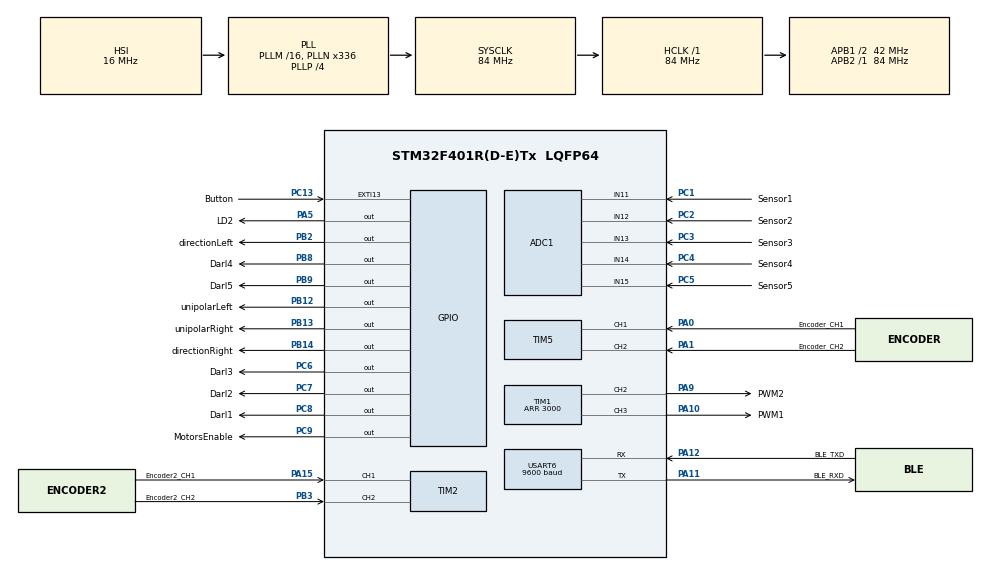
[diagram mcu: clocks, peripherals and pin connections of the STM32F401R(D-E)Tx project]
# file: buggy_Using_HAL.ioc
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ADC1.Channel-0\#ChannelRegularConversion=ADC_CHANNEL_15
ADC1.Channel-1\#ChannelRegularConversion=ADC_CHANNEL_14
ADC1.Channel-2\#ChannelRegularConversion=ADC_CHANNEL_13
ADC1.Channel-3\#ChannelRegularConversion=ADC_CHANNEL_12
ADC1.Channel-4\#ChannelRegularConversion=ADC_CHANNEL_11
ADC1.ContinuousConvMode=ENABLE
ADC1.DMAContinuousRequests=ENABLE
ADC1.DiscontinuousConvMode=DISABLE
ADC1.NbrOfConversion=5
ADC1.NbrOfConversionFlag=1
ADC1.Rank-0\#ChannelRegularConversion=1
ADC1.Rank-1\#ChannelRegularConversion=2
ADC1.Rank-2\#ChannelRegularConversion=3
ADC1.Rank-3\#ChannelRegularConversion=4
ADC1.Rank-4\#ChannelRegularConversion=5
ADC1.SamplingTime-0\#ChannelRegularConversion=ADC_SAMPLETIME_15CYCLES
ADC1.SamplingTime-1\#ChannelRegularConversion=ADC_SAMPLETIME_15CYCLES
ADC1.SamplingTime-2\#ChannelRegularConversion=ADC_SAMPLETIME_15CYCLES
ADC1.SamplingTime-3\#ChannelRegularConversion=ADC_SAMPLETIME_15CYCLES
ADC1.SamplingTime-4\#ChannelRegularConversion=ADC_SAMPLETIME_15CYCLES
ADC1.master=1
Dma.ADC1.0.Direction=DMA_PERIPH_TO_MEMORY
Dma.ADC1.0.FIFOMode=DMA_FIFOMODE_DISABLE
Dma.ADC1.0.Instance=DMA2_Stream0
Dma.ADC1.0.MemDataAlignment=DMA_MDATAALIGN_HALFWORD
Dma.ADC1.0.MemInc=DMA_MINC_ENABLE
Dma.ADC1.0.Mode=DMA_CIRCULAR
Dma.ADC1.0.PeriphDataAlignment=DMA_PDATAALIGN_HALFWORD
Dma.ADC1.0.PeriphInc=DMA_PINC_DISABLE
Dma.ADC1.0.Priority=DMA_PRIORITY_LOW
Dma.Request0=ADC1
Mcu.Family=STM32F4
Mcu.Name=STM32F401R(D-E)Tx
Mcu.Package=LQFP64
NVIC.DMA2_Stream0_IRQn=true\:0\:0\:false\:false\:true\:false\:true\:true
NVIC.EXTI15_10_IRQn=true\:0\:0\:false\:false\:true\:true\:true\:true
NVIC.PriorityGroup=NVIC_PRIORITYGROUP_0
NVIC.TIM2_IRQn=true\:0\:0\:false\:false\:true\:true\:true\:true
NVIC.TIM3_IRQn=true\:0\:0\:false\:false\:true\:true\:true\:true
NVIC.TIM4_IRQn=true\:0\:0\:false\:false\:true\:true\:true\:true
NVIC.TIM5_IRQn=true\:0\:0\:false\:false\:true\:true\:true\:true
NVIC.USART6_IRQn=true\:0\:0\:false\:false\:true\:true\:true\:true
PA0-WKUP.GPIO_Label=Encoder_CH1
PA0-WKUP.GPIO_PuPd=GPIO_PULLDOWN
PA0-WKUP.Signal=S_TIM5_CH1
PA1.GPIO_Label=Encoder_CH2
PA1.GPIO_PuPd=GPIO_PULLDOWN
PA1.Signal=S_TIM5_CH2
PA10.GPIO_Label=PWM1
PA10.GPIO_PuPd=GPIO_PULLDOWN
PA10.Signal=S_TIM1_CH3
PA11.GPIO_Label=BLE_RXD
PA11.Mode=Asynchronous
PA11.Signal=USART6_TX
PA12.GPIO_Label=BLE_TXD
PA12.Mode=Asynchronous
PA12.Signal=USART6_RX
PA13.Signal=SYS_JTMS-SWDIO
PA15.GPIO_Label=Encoder2_CH1
PA15.GPIO_PuPd=GPIO_PULLDOWN
PA15.Signal=S_TIM2_CH1_ETR
PA2.GPIO_PuPd=GPIO_PULLDOWN
PA2.Signal=USART2_TX
PA3.GPIO_PuPd=GPIO_PULLDOWN
PA3.Signal=USART2_RX
PA5.GPIO_Label=LD2
PA5.Signal=GPIO_Output
PA9.GPIO_Label=PWM2
PA9.GPIO_PuPd=GPIO_PULLDOWN
PA9.Signal=S_TIM1_CH2
PB12.GPIO_Label=unipolarLeft
PB12.GPIO_PuPd=GPIO_PULLDOWN
PB12.PinState=GPIO_PIN_RESET
PB12.Signal=GPIO_Output
PB13.GPIO_Label=unipolarRight
PB13.GPIO_ModeDefaultOutputPP=GPIO_MODE_OUTPUT_PP
PB13.GPIO_PuPd=GPIO_PULLDOWN
PB13.PinState=GPIO_PIN_RESET
PB13.Signal=GPIO_Output
PB14.GPIO_Label=directionRight
PB14.GPIO_PuPd=GPIO_PULLDOWN
PB14.PinState=GPIO_PIN_RESET
PB14.Signal=GPIO_Output
PB2.GPIO_Label=directionLeft
PB2.GPIO_PuPd=GPIO_PULLDOWN
PB2.Signal=GPIO_Output
PB3.GPIO_Label=Encoder2_CH2
PB3.GPIO_PuPd=GPIO_PULLDOWN
PB3.Signal=S_TIM2_CH2
PB8.GPIO_Label=Darl4
PB8.GPIO_PuPd=GPIO_PULLDOWN
PB8.PinState=GPIO_PIN_SET
PB8.Signal=GPIO_Output
PB9.GPIO_Label=Darl5
PB9.GPIO_PuPd=GPIO_PULLDOWN
PB9.PinState=GPIO_PIN_SET
PB9.Signal=GPIO_Output
PC1.GPIO_Label=Sensor1
PC1.Signal=ADCx_IN11
PC13-ANTI_TAMP.GPIO_Label=Button
PC13-ANTI_TAMP.GPIO_ModeDefaultEXTI=GPIO_MODE_IT_FALLING
PC13-ANTI_TAMP.GPIO_PuPd=GPIO_PULLUP
PC13-ANTI_TAMP.Signal=GPXTI13
PC2.GPIO_Label=Sensor2
PC2.Signal=ADCx_IN12
PC3.GPIO_Label=Sensor3
PC3.Signal=ADCx_IN13
PC4.GPIO_Label=Sensor4
PC4.Signal=ADCx_IN14
PC5.GPIO_Label=Sensor5
PC5.Signal=ADCx_IN15
PC6.GPIO_Label=Darl3
PC6.GPIO_PuPd=GPIO_PULLDOWN
PC6.PinState=GPIO_PIN_SET
PC6.Signal=GPIO_Output
PC7.GPIO_Label=Darl2
PC7.GPIO_PuPd=GPIO_PULLDOWN
PC7.PinState=GPIO_PIN_SET
PC7.Signal=GPIO_Output
PC8.GPIO_Label=Darl1
PC8.GPIO_PuPd=GPIO_PULLDOWN
PC8.PinState=GPIO_PIN_SET
PC8.Signal=GPIO_Output
PC9.GPIO_Label=MotorsEnable
PC9.GPIO_PuPd=GPIO_PULLDOWN
PC9.PinState=GPIO_PIN_RESET
PC9.Signal=GPIO_Output
PH0\ -\ OSC_IN.Mode=HSE-External-Oscillator
PH0\ -\ OSC_IN.Signal=RCC_OSC_IN
PH1\ -\ OSC_OUT.Mode=HSE-External-Oscillator
PH1\ -\ OSC_OUT.Signal=RCC_OSC_OUT
ProjectManager.HeapSize=0x200
ProjectManager.StackSize=0x400
ProjectManager.TargetToolchain=STM32CubeIDE
RCC.48MHZClocksFreq_Value=48000000
RCC.AHBFreq_Value=84000000
RCC.APB1CLKDivider=RCC_HCLK_DIV2
RCC.APB1Freq_Value=42000000
RCC.APB1TimFreq_Value=84000000
RCC.APB2Freq_Value=84000000
RCC.APB2TimFreq_Value=84000000
RCC.CortexFreq_Value=84000000
RCC.HCLKFreq_Value=84000000
RCC.HSE_VALUE=8000000
RCC.HSI_VALUE=16000000
RCC.LSE_VALUE=32768
RCC.PLLN=336
RCC.PLLP=RCC_PLLP_DIV4
RCC.PLLQ=7
RCC.SYSCLKFreq_VALUE=84000000
RCC.SYSCLKSource=RCC_SYSCLKSOURCE_PLLCLK
RCC.VCOOutputFreq_Value=336000000
SH.ADCx_IN11.0=ADC1_IN11,IN11
SH.ADCx_IN12.0=ADC1_IN12,IN12
SH.ADCx_IN13.0=ADC1_IN13,IN13
SH.ADCx_IN14.0=ADC1_IN14,IN14
SH.ADCx_IN15.0=ADC1_IN15,IN15
SH.S_TIM1_CH2.0=TIM1_CH2,PWM Generation2 CH2
SH.S_TIM1_CH3.0=TIM1_CH3,PWM Generation3 CH3
SH.S_TIM2_CH1_ETR.0=TIM2_CH1,Encoder_Interface
SH.S_TIM2_CH2.0=TIM2_CH2,Encoder_Interface
SH.S_TIM5_CH1.0=TIM5_CH1,Encoder_Interface
SH.S_TIM5_CH2.0=TIM5_CH2,Encoder_Interface
TIM1.Channel-PWM\ Generation2\ CH2=TIM_CHANNEL_2
TIM1.Channel-PWM\ Generation3\ CH3=TIM_CHANNEL_3
TIM1.Period=3000
TIM2.EncoderMode=TIM_ENCODERMODE_TI12
TIM3.Period=59999
TIM3.Prescaler=13
TIM4.Period=49999
TIM4.Prescaler=167
TIM5.EncoderMode=TIM_ENCODERMODE_TI12
USART6.BaudRate=9600
USART6.VirtualMode=VM_ASYNC
VP_TIM3_VS_ClockSourceINT.Mode=Internal
VP_TIM4_VS_ClockSourceINT.Mode=Internal
board=NUCLEO-F401RE

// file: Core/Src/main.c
/* USER CODE BEGIN Header */
/**
  ******************************************************************************
  * @file           : main.c
  * @brief          : Main program body
  ******************************************************************************
  * @attention
  *
  * Copyright (c) 2024 STMicroelectronics.
  * All rights reserved.
  *
  * This software is licensed under terms that can be found in the LICENSE file
  * in the root directory of this software component.
  * If no LICENSE file comes with this software, it is provided AS-IS.
  *
  ******************************************************************************
  */
/* USER CODE END Header */
#include "main.h"
#include "adc.h"
#include "dma.h"
#include "tim.h"
#include "usart.h"
#include "gpio.h"

/* USER CODE BEGIN Includes */
#include "Motors.h"
#include "Encoder.h"
#include "PID.h"
#include "StateMachine.h"

/* USER CODE END Includes */

/* USER CODE BEGIN PV */

//motor_instance leftMotor, rightMotor;

// Flags for state machine

uint16_t ADCREAD[5];
char bleChar;
/* USER CODE END PV */

void SystemClock_Config(void);

int main(void)
{

  /* USER CODE BEGIN 1 */
	states Current_State = RESET_StateMachine;

  /* USER CODE END 1 */

  /* MCU Configuration--------------------------------------------------------*/

  /* Reset of all peripherals, Initializes the Flash interface and the Systick. */
  HAL_Init();

  /* Configure the system clock */
  SystemClock_Config();

  /* Initialize all configured peripherals */
  MX_GPIO_Init();
  MX_DMA_Init();
  MX_TIM5_Init();
  MX_TIM1_Init();
  MX_TIM2_Init();
  MX_ADC1_Init();
  MX_TIM3_Init();
  MX_USART6_UART_Init();
  MX_TIM4_Init();
  /* USER CODE BEGIN 2 */

  MOTORS_Reset();
  MOTORS_Disable();

//  HAL_ADC_Start_DMA(&hadc1,ADCREAD, 5);

//  HAL_GPIO_TogglePin(Darl1_GPIO_Port, Darl1_Pin);
//  HAL_GPIO_TogglePin(Darl2_GPIO_Port, Darl2_Pin);
//  HAL_GPIO_TogglePin(Darl3_GPIO_Port, Darl3_Pin);
//  HAL_GPIO_TogglePin(Darl4_GPIO_Port, Darl4_Pin);
//  HAL_GPIO_TogglePin(Darl5_GPIO_Port, Darl5_Pin);
  //HAL_UART_Receive_IT(&huart2, bleChar, 1);
  /* USER CODE END 2 */

  /* Infinite loop */
  /* USER CODE BEGIN WHILE */
  while (1)
  {
//	  HAL_UART_Receive(&huart6, bleChar, 1, 100);
//	  if (bleChar == 'A') {
//	  		HAL_GPIO_WritePin(GPIOA, LD2_Pin, 1);
//	  	}-
//	  	else if (bleChar == 'C') {
//	  		HAL_GPIO_WritePin(GPIOA, LD2_Pin, 0);
//	  	}
    /* USER CODE END WHILE */

  }
}

void SystemClock_Config(void)
{
  RCC_OscInitTypeDef RCC_OscInitStruct = {0};
  RCC_ClkInitTypeDef RCC_ClkInitStruct = {0};

  /** Configure the main internal regulator output voltage
  */
  __HAL_RCC_PWR_CLK_ENABLE();
  __HAL_PWR_VOLTAGESCALING_CONFIG(PWR_REGULATOR_VOLTAGE_SCALE2);

  /** Initializes the RCC Oscillators according to the specified parameters
  * in the RCC_OscInitTypeDef structure.
  */
  RCC_OscInitStruct.OscillatorType = RCC_OSCILLATORTYPE_HSI;
  RCC_OscInitStruct.HSIState = RCC_HSI_ON;
  RCC_OscInitStruct.HSICalibrationValue = RCC_HSICALIBRATION_DEFAULT;
  RCC_OscInitStruct.PLL.PLLState = RCC_PLL_ON;
  RCC_OscInitStruct.PLL.PLLSource = RCC_PLLSOURCE_HSI;
  RCC_OscInitStruct.PLL.PLLM = 16;
  RCC_OscInitStruct.PLL.PLLN = 336;
  RCC_OscInitStruct.PLL.PLLP = RCC_PLLP_DIV4;
  RCC_OscInitStruct.PLL.PLLQ = 7;
  if (HAL_RCC_OscConfig(&RCC_OscInitStruct) != HAL_OK)
  {
    Error_Handler();
  }

  /** Initializes the CPU, AHB and APB buses clocks
  */
  RCC_ClkInitStruct.ClockType = RCC_CLOCKTYPE_HCLK|RCC_CLOCKTYPE_SYSCLK
                              |RCC_CLOCKTYPE_PCLK1|RCC_CLOCKTYPE_PCLK2;
  RCC_ClkInitStruct.SYSCLKSource = RCC_SYSCLKSOURCE_PLLCLK;
  RCC_ClkInitStruct.AHBCLKDivider = RCC_SYSCLK_DIV1;
  RCC_ClkInitStruct.APB1CLKDivider = RCC_HCLK_DIV2;
  RCC_ClkInitStruct.APB2CLKDivider = RCC_HCLK_DIV1;

  if (HAL_RCC_ClockConfig(&RCC_ClkInitStruct, FLASH_LATENCY_2) != HAL_OK)
  {
    Error_Handler();
  }
}

/* USER CODE BEGIN 4 */
//void HAL_ADC_ConvCpltCallback(ADC_HandleTypeDef* hadc) {
//// empty for now
//
//}

//void HAL_UART_RxCpltCallback(UART_HandleTypeDef *huart)
//{
//	if (bleChar == 'A') {
//		HAL_GPIO_WritePin(GPIOA, LD2_Pin, 1);
//	}
//	else if (bleChar == 'C') {
//		HAL_GPIO_WritePin(GPIOA, LD2_Pin, 0);
//	}
//	HAL_UART_Receive_IT(&huart2, bleChar, 1);
//
//}

/* USER CODE END 4 */

void Error_Handler(void)
{
  __disable_irq();
  while (1)
  {
  }
}
